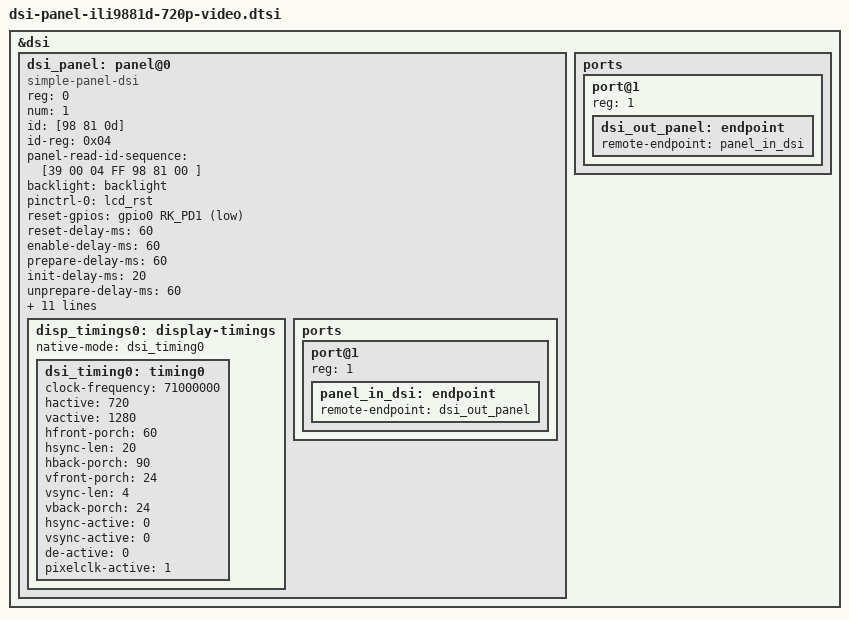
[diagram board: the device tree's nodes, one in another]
#if 1
&dsi {
	dsi_panel: panel@0 {
		status = "okay";
		compatible = "simple-panel-dsi";
		reg = <0>;
		num = <1>;
		id = [98 81 0d];
		id-reg = <0x04>;
		panel-read-id-sequence= [39 00 04 FF 98 81 00 ];
		backlight = <&backlight>;
		pinctrl-names = "default";
		pinctrl-0 = <&lcd_rst>;
		reset-gpios = <&gpio0 RK_PD1 GPIO_ACTIVE_LOW>;
		reset-delay-ms = <60>;
		enable-delay-ms = <60>;
		prepare-delay-ms = <60>;
		init-delay-ms = <20>;
		unprepare-delay-ms = <60>;
		disable-delay-ms = <60>;
		width-mm = <68>;
		height-mm = <121>;
		dsi,flags = <(MIPI_DSI_MODE_VIDEO | MIPI_DSI_MODE_VIDEO_BURST | MIPI_DSI_MODE_LPM)>;
		dsi,format = <MIPI_DSI_FMT_RGB888>;
		dsi,lanes  = <4>;
		panel-init-sequence = [
            39 00 04 ff 98 81 03
			23 00 02 01 00
			23 00 02 02 00
			23 00 02 03 73
			23 00 02 04 03
			23 00 02 05 00
			23 00 02 06 0a
			23 00 02 07 00
			23 00 02 08 00
			23 00 02 09 01
			23 00 02 0a 00
			23 00 02 0b 00
			23 00 02 0c 01
			23 00 02 0d 00
			23 00 02 0e 00
			23 00 02 0f 1d

			23 00 02 10 0d
			23 00 02 11 00
			23 00 02 12 00
			23 00 02 13 00
			23 00 02 14 00
			23 00 02 15 00
			23 00 02 16 00
			23 00 02 17 00
			23 00 02 18 00
			23 00 02 19 00
			23 00 02 1a 00
			23 00 02 1b 00
			23 00 02 1c 00
			23 00 02 1d 00
			23 00 02 1e 40
			23 00 02 1f 80

			23 00 02 20 06
			23 00 02 21 02
			23 00 02 22 00
			23 00 02 23 00
			23 00 02 24 00
			23 00 02 25 00
			23 00 02 26 00
			23 00 02 27 00
			23 00 02 28 33
			23 00 02 29 03
			23 00 02 2a 00
			23 00 02 2b 00
			23 00 02 2c 00
			23 00 02 2d 00
			23 00 02 2e 00
			23 00 02 2f 00

			23 00 02 30 00
			23 00 02 31 00
			23 00 02 32 00
			23 00 02 33 00
			23 00 02 34 04
			23 00 02 35 00
			23 00 02 36 00
			23 00 02 37 00
			23 00 02 38 3c
			23 00 02 39 35
			23 00 02 3a 01
			23 00 02 3b 40
			23 00 02 3c 00
			23 00 02 3d 01
			23 00 02 3e 00
			23 00 02 3f 00

			23 00 02 40 00
			23 00 02 41 88
			23 00 02 42 00
			23 00 02 43 00
			23 00 02 44 1f

			23 00 02 50 01
			23 00 02 51 23
			23 00 02 52 45
			23 00 02 53 67
			23 00 02 54 89
			23 00 02 55 ab
			23 00 02 56 01
			23 00 02 57 23
			23 00 02 58 45
			23 00 02 59 67
			23 00 02 5a 89
			23 00 02 5b ab
			23 00 02 5c cd
			23 00 02 5d ef
			23 00 02 5e 11
			23 00 02 5f 01

			23 00 02 60 00
			23 00 02 61 15
			23 00 02 62 14
			23 00 02 63 0e
			23 00 02 64 0f
			23 00 02 65 0c
			23 00 02 66 0d
			23 00 02 67 06
			23 00 02 68 02
			23 00 02 69 07
			23 00 02 6a 02
			23 00 02 6b 02
			23 00 02 6c 02
			23 00 02 6d 02
			23 00 02 6e 02
			23 00 02 6f 02

			23 00 02 70 02
			23 00 02 71 02
			23 00 02 72 02
			23 00 02 73 02
			23 00 02 74 02
			23 00 02 75 01
			23 00 02 76 00
			23 00 02 77 14
			23 00 02 78 15
			23 00 02 79 0e
			23 00 02 7a 0f
			23 00 02 7b 0c
			23 00 02 7c 0d
			23 00 02 7d 06
			23 00 02 7e 02
			23 00 02 7f 07

			23 00 02 80 02
			23 00 02 81 02
			23 00 02 82 02
			23 00 02 83 02
			23 00 02 84 02
			23 00 02 85 02
			23 00 02 86 02
			23 00 02 87 02
			23 00 02 88 02
			23 00 02 89 02
			23 00 02 8a 02

			39 00 04 ff 98 81 04
			23 00 02 6D 08
			23 00 02 6F 05
			23 00 02 00 80
			23 00 02 70 00
			23 00 02 71 00
			23 00 02 66 fe
			23 00 02 82 0f
			23 00 02 84 0f
			23 00 02 85 0d
			23 00 02 3a 24
			23 00 02 32 ac
			23 00 02 8c 80
			23 00 02 3c f5
			23 00 02 31 45 
			23 00 02 B5 07 
			23 00 02 88 33

			39 00 04 ff 98 81 01
			23 00 02 22 09 
			23 00 02 31 00
			23 00 02 53 8a 
			23 00 02 55 A2 
			23 00 02 50 81 
			23 00 02 51 85	
			23 00 02 60 20
			23 00 02 61 00
			23 00 02 62 0d
			23 00 02 63 00

			23 00 02 a0 00
			23 00 02 a1 1a
			23 00 02 a2 28
			23 00 02 a3 18
			23 00 02 a4 16
			23 00 02 a5 29
			23 00 02 a6 1d
			23 00 02 a7 1e
			23 00 02 a8 84
			23 00 02 a9 1c
			23 00 02 aa 28
			23 00 02 ab 75
			23 00 02 ac 1a
			23 00 02 ad 19
			23 00 02 ae 4d
			23 00 02 af 22
			23 00 02 b0 28
			23 00 02 b1 54
			23 00 02 b2 66
			23 00 02 b3 39  

			23 00 02 c0 00
			23 00 02 c1 1a
			23 00 02 c2 28
			23 00 02 c3 13
			23 00 02 c4 16
			23 00 02 c5 29
			23 00 02 c6 1d
			23 00 02 c7 1e
			23 00 02 c8 84
			23 00 02 c9 1c
			23 00 02 ca 28
			23 00 02 cb 75
			23 00 02 cc 1a
			23 00 02 cd 19
			23 00 02 ce 4d
			23 00 02 cf 22
			23 00 02 d0 28
			23 00 02 d1 54
			23 00 02 d2 66
			23 00 02 d3 39 
			
			39 00 04 ff 98 81 00
			39 00 02 35 00 
			39 00 02 36 03 
			05 78 01 11
			05 14 01 29
		];

		panel-exit-sequence = [
			05 32 01 28
			05 78 01 10
		];

		disp_timings0: display-timings {
			native-mode = <&dsi_timing0>;
			dsi_timing0: timing0 {
				clock-frequency = <71000000>;
				hactive = <720>;
				vactive = <1280>;
				hfront-porch = <60>;
				hsync-len = <20>;
				hback-porch = <90>;
				vfront-porch = <24>;
				vsync-len = <4>;
				vback-porch = <24>;
				hsync-active = <0>;
				vsync-active = <0>;
				de-active = <0>;
				pixelclk-active = <1>;
			};
		};

		ports {
			#address-cells = <1>;
			#size-cells = <0>;

			port@1 {
				reg = <1>;
				panel_in_dsi: endpoint {
					remote-endpoint = <&dsi_out_panel>;
				};
			};
		};
	};

	ports {
		#address-cells = <1>;
		#size-cells = <0>;

		port@1 {
			reg = <1>;
			dsi_out_panel: endpoint {
				remote-endpoint = <&panel_in_dsi>;
			};
		};
	};

};

#endif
